# moonlight_application register map
Vendor: Nordic Semiconductor; Series: lumos; File version: 1
CPU: CM33 r0p4, little endian, MPU, FPU, 3 interrupt priority bits, 176 interrupts, 4 SAU regions
Registers are 32-bit, read-write, reset 0x0 unless marked. A register's access mark holds for its fields unless they carry their own. Offsets are from the block's base; [hi:lo] are bit positions; lines under a group give offsets from that group; {n}, {i} and the like mark numbered series; 'fields as' and 'values as' point back to an identical list.

## GLOBAL_RADIO_NS (part 4 of 4) — 2.4 GHz radio 0
Base 0x4008A000
Same registers: GLOBAL_RADIO_S 0x5008A000
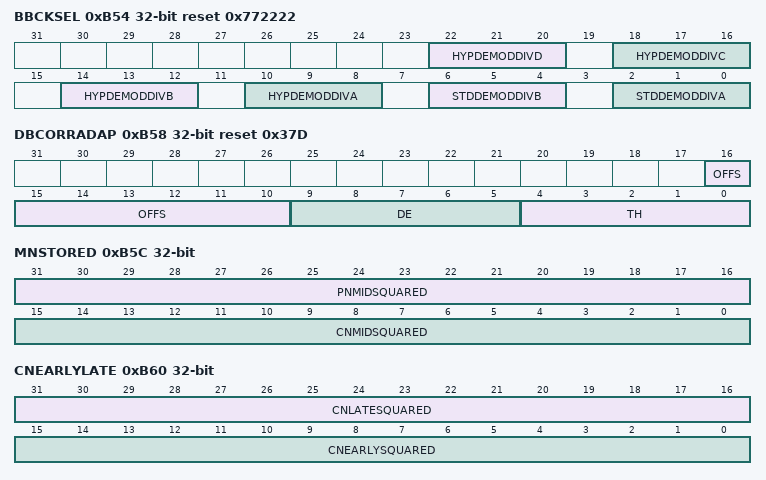
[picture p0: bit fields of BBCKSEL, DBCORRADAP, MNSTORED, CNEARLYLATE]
0xB54 BBCKSEL reset 0x772222 — Clock rates
  [22:20] HYPDEMODDIVD — Hyper demod clock divider D (max 4MHz)
    3=4M (Clock 4MHz); 4=2M (Clock 2MHz); 5=1M (Clock 1MHz); 6=500K (Clock 500kHz); 7=Disabled (Clock OFF)
  [18:16] HYPDEMODDIVC — Hyper demod clock divider C (max 8MHz)
    2=8M (Clock 8MHz); 3=4M (Clock 4MHz); 4=2M (Clock 2MHz); 5=1M (Clock 1MHz); 6=500K (Clock 500kHz); 7=Disabled (Clock OFF)
  [14:12] HYPDEMODDIVB — Hyper demod clock divider B
    0=32M (Clock 32MHz); 1=16M (Clock 16MHz); 2=8M (Clock 8MHz); 3=4M (Clock 4MHz); 4=2M (Clock 2MHz); 5=1M (Clock 1MHz); 6=500K (Clock 500kHz); 7=Disabled (Clock OFF)
  [10:8] HYPDEMODDIVA — Hyper demod clock divider A
    values as HYPDEMODDIVB
  [6:4] STDDEMODDIVB — Standard demod clock divider B
    values as HYPDEMODDIVB
  [2:0] STDDEMODDIVA — Standard demod clock divider A
    values as HYPDEMODDIVB
0xB58 DBCORRADAP reset 0x37D — Adaptive thresholds for double correlator.
  [16:10] OFFS — Offset for comparing between current and historical DBC magnitude
  [9:5] DE — A ratio to decay the DBC ration threshold when using adaptive threshold and a weak peak is found.
  [4:0] TH — A ratio to update the DBC ratio threshold when adaptive threshold is enabled and a strong peak is found. Fraction of highest correlator match historically seen. Setting of 0.90625 is default.
0xB5C MNSTORED ro — Stored value of Cn and Pn from the double correlator at the last detect
  [31:16] PNMIDSQUARED — Squared value of Cn which can be used to find Mn associated with the last double correlator detect
  [15:0] CNMIDSQUARED — Squared value of Cn which can be used to find Mn associated with the last double correlator detect
0xB60 CNEARLYLATE ro — The Cn value associated with the clock cycle before and after the actually double correlator peak was found (detect)
  [31:16] CNLATESQUARED — Squared value of Cn after the peak
  [15:0] CNEARLYSQUARED — Squared value of Cn before the peak
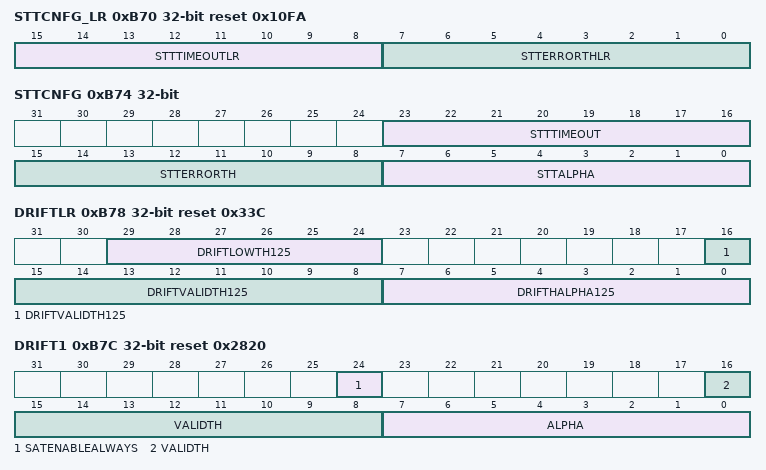
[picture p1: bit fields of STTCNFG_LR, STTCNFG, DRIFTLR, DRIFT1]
0xB70 STTCNFG_LR reset 0x10FA — Strobe time tracking configuration in long range mode
  [15:8] STTTIMEOUTLR — Strobe time tracking timeout in BLE LR mode
  [7:0] STTERRORTHLR — Strobe time tracking error threshold in BLE LR mode
0xB74 STTCNFG — Strobe time tracking Configuration (Symbol Timing)
  [23:16] STTTIMEOUT — Strobe time tracking: adjustment timeout (min distance in symbolperiods between strobe adjustments in same direction)
  [15:8] STTERRORTH — Strobe time tracking: strobe time error threshold
  [7:0] STTALPHA — Strobe time tracking: IIR filter alpha
0xB78 DRIFTLR reset 0x33C — Drift Controls in Long Range
  [29:24] DRIFTLOWTH125 — Override value for driftLowTh, drift estimator (despreadLELLong)
  [16:8] DRIFTVALIDTH125 — Override value for driftValidTh, drift estimator (despreadLELLong)
  [7:0] DRIFTHALPHA125 — Override value for IIR feedback , drift estimator (despreadLELLong)
0xB7C DRIFT1 reset 0x2820 — Drift Estimator configuration
  [24] SATENABLEALWAYS — Enable saturation in drift calculator for all modes
  [16:8] VALIDTH — Override value for driftValidTh, drift estimator (hypermode)
  [7:0] ALPHA — Override value for IIR feedback , drift estimator (hypermode)
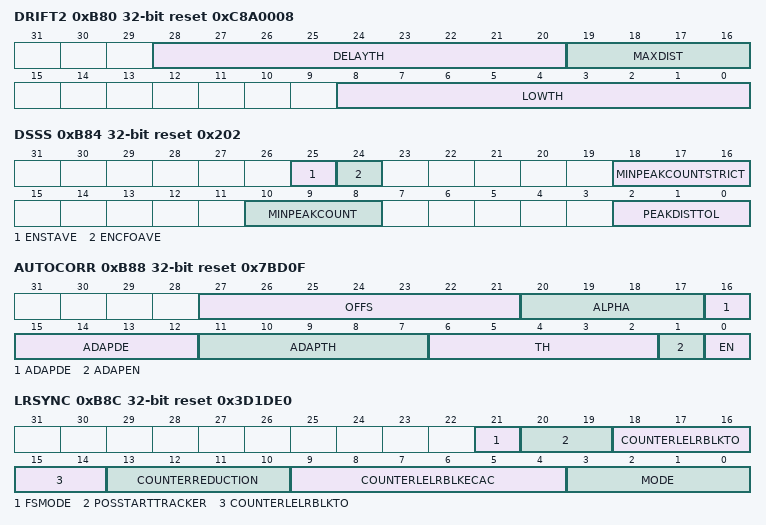
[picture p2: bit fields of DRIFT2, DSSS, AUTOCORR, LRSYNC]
0xB80 DRIFT2 reset 0xC8A0008 — Drift Estimator configuration
  [28:20] DELAYTH — Override value for driftDelayTh, drift estimator (hypermode)
  [19:16] MAXDIST — Override value for driftMaxDist, drift estimator (hypermode)
  [8:0] LOWTH — Override value for driftLowTh, drift estimator (hypermode)
0xB84 DSSS reset 0x202 — DSSS synchronizer trim values
  [25] ENSTAVE — Enable strobe time averaging
  [24] ENCFOAVE — Enable CFO averaging
  [18:16] MINPEAKCOUNTSTRICT — Min number of peaks to detect before resyncing to another preamble while already working on a previous preamble in BleLrx. Also applies for Ieee 802.15.4 mode
  [10:8] MINPEAKCOUNT — Override for dsssMinPeakCount
  [2:0] PEAKDISTTOL — Override for dsssPeakDistanceTolerance
0xB88 AUTOCORR reset 0x7BD0F — Autocorrelator configuration
  [27:21] OFFS — Offset for comparing between current and historical AC magnitude
  [20:17] ALPHA — Gain factor for low pass filter used to smoothen autocorrelator output. Set to 0000 indicates to select Max filter instead of LPF.
  [16:12] ADAPDE — A ratio to decay the autocorrelator ratio threshold when using adaptive threshold and a weak peak is found.
  [11:7] ADAPTH — A ratio to update the autocorrelator ratio threshold when adaptive threshold is enabled and a strong peak is found. Fraction of highest correlator match historically seen. Setting of 0.8125 is default.
  [6:2] TH — Default correlator threshold for deciding if valid correlator match is seen. Low setting of 0.10 is default.
  [1] ADAPEN — Enable adaptive autocorrelator threshold settings based on historically observed correlator output values.
  [0] EN — Enable autocorrelator gating of peaks.
0xB8C LRSYNC reset 0x3D1DE0 — LrSyncEngine configuration
  [21] FSMODE — Select between classic and MLSD based frame sync
    0=classic mode; 1=MLSD mode
  [20:19] POSSTARTTRACKER — A toggle to tell when to start the trackers inside each LelrBlk125.
    0=disabled for all times; 1=enabled after FEC1 is decoded; 2=enabled after frame sync is achieved; 3=enabled after LelrBlk125 is activated
  [18:14] COUNTERLELRBLKTO — A counter is used to reset the LelrBlk125 block that is active. It counts the number of outputs from DeSpreadLELong and compares it with this configured value to see whether a timeout event happens. The range is 32 to 60. Default value is 52.
  [13:10] COUNTERREDUCTION — When a strong peak event is triggered and the average peak strength is higher than the history stored in the block, the timeout counter is reduced by the number configured in this register. The default value is 7.
  [9:4] COUNTERLELRBLKECAC — A counter is used to indicate the time window of e-CAC check. It counts the number of outputs from DeSpreadLELong and compares it with this configured value to see whether e-CAC result is valid.
  [3:0] MODE — Modifying how the multiple lr125Front modules are used when synchronizing.
    0=AllFrontends (Use all the front ends); 1=OneFrontend (Use only one front end)
0xB90 QOVERRIDE26 reset 0x1 — Override for selecting whether to use LrSyncEngine or the classic demodulator.
  [0] USELRSYNCENGINE — Select whether to use LrSyncEngine or the classic demodulator.
    0=Classic (use classic demodulator); 1=LrSyncEngine (Use LrSyncEngine demodulator)
0xB94 QOVERRIDE27 reset 0x1 — Override for selecting whether to use enhanced IEEE 802.15.4 or the classic IEEE 802.15.4 demodulator.
  [0] USE154SYNCENGINE — Select whether to use enhanced IEEE 802.15.4 or the classic IEEE 802.15.4 demodulator.
    0=Classic (Use classic demodulator); 1=Ieee154SyncEngine (Use IEEE 802.15.4 sync demodulator)
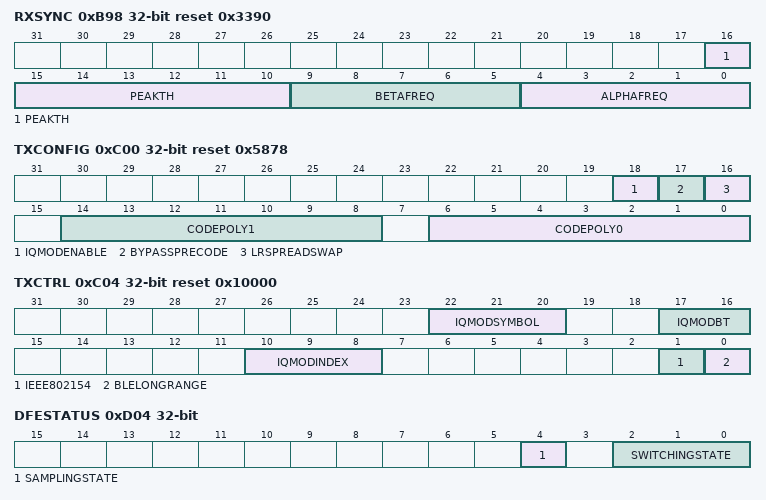
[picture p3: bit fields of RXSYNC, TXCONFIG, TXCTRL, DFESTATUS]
0xB98 RXSYNC reset 0x3390 — RxSyncEngine configuration
  [16:10] PEAKTH — Threshold value for peak strength. Default value is 0001100, corresponds to 0.31.
  [9:5] BETAFREQ — Coefficient to update frequency offset. Default value is 11100, corresponds to 7/8.
  [4:0] ALPHAFREQ — Coefficient to update frequency offset. Default value is 10000, corresponds to 1/2.
0xC00 TXCONFIG reset 0x5878 — Tx configuration
  [18] IQMODENABLE — Enable IQ modulator
    0=Disabled; 1=Enabled
  [17] BYPASSPRECODE — Bypass MSK precoding
    0=NotBypassed (Disable); 1=Bypassed (Enable)
  [16] LRSPREADSWAP — Swap pattern mapping. Default 0, 0 is mapped to a 0011 sequence, 1 is mapped to a 1100 sequence. If swap bit is set, 1 is mapped to a 0011 sequence, 0 is mapped to a 1100 sequence.
  [14:8] CODEPOLY1 — Code polynomial 1
  [6:0] CODEPOLY0 — Code polynomial 0
0xC04 TXCTRL reset 0x10000 — Tx control
  [22:20] IQMODSYMBOL — IQMOD additional symbol mapping not set by MODE(Future)
  [17:16] IQMODBT — IQMOD GFSK bandwidth
    0=0BT55 (BT=0.55); 1=0BT60 (BT=0.60)
  [10:8] IQMODINDEX — IQMOD modulation index
    0=ModIndex0h25 (Modulation index = 0.25(Future)); 1=ModIndex0h32 (Modulation index = 0.32(Future)); 2=ModIndex0h5 (Modulation index = 0.5(Future)); 3=ModIndex1h0 (Modulation index = 1(Future)); 4=ModIndex2h0 (Modulation index = 2(Future))
  [1] IEEE802154 — Enable Tx for Ieee802154_250Kbit mode and long range modes (Do not enable both Ieee802154_250Kbit and long range)
    0=Disabled (Disable Tx for Ieee802154_250Kbit mode); 1=Enabled (Enable Tx for Ieee802154_250Kbit mode)
  [0] BLELONGRANGE — Enable Tx for BLE long range modes (Do not enable both Ieee802154_250Kbit and BLE long range)
    0=Disabled (Disable Tx for BLE long range modes); 1=Enabled (Enable Tx for BLE long range modes)
0xD00 DFEMODE — Whether to use Angle-of-Arrival (AOA) or Angle-of-Departure (AOD)
  [1:0] DFEOPMODE — Direction finding operation mode
    0=Disabled (Direction finding mode disabled); 2=AoD (Direction finding mode set to AoD); 3=AoA (Direction finding mode set to AoA)
0xD04 DFESTATUS ro — DFE status information
  [4] SAMPLINGSTATE — Internal state of sampling state machine
    0=Idle (Sampling state Idle); 1=Sampling state Sampling
  [2:0] SWITCHINGSTATE — Internal state of switching state machine
    0=Idle (Switching state Idle); 1=Offset (Switching state Offset); 2=Guard (Switching state Guard); 3=Ref (Switching state Ref); 4=Switching state Switching; 5=Ending (Switching state Ending)
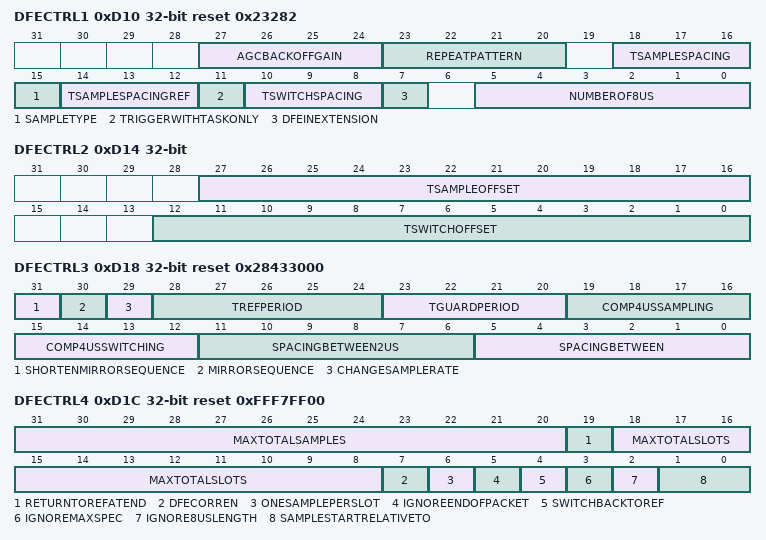
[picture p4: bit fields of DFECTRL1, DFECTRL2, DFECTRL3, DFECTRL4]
0xD10 DFECTRL1 reset 0x23282 — Various configuration for Direction finding
  [27:24] AGCBACKOFFGAIN — Gain will be lowered by the specified number of gain steps at the start of CTE
  [23:20] REPEATPATTERN — Repeat every antenna pattern N times.
    0=NoRepeat (Do not repeat (1 time in total))
  [18:16] TSAMPLESPACING — Interval between samples in the SWITCHING period when CTEINLINECTRLEN is 0
    1=4us; 2=2us; 3=1us; 4=500ns (0.5us); 5=250ns (0.25us); 6=125ns (0.125us)
  [15] SAMPLETYPE — Whether to sample I/Q or magnitude/phase
    0=IQ (Complex samples in I and Q); 1=MagPhase (Complex samples as magnitude and phase)
  [14:12] TSAMPLESPACINGREF — Interval between samples in the REFERENCE period
    0=8us; 1=4us; 2=2us; 3=1us; 4=500ns (0.5us); 5=250ns (0.25us); 6=125ns (0.125us)
  [11] TRIGGERWITHTASKONLY — Trigger AoA/AoD procedure using only task
    1=OnlyTask (Only allow triggering a procedure with TASKS_DFESTART); 0=Multiple (Trigger also with other signals)
  [10:8] TSWITCHSPACING — Interval between every time the antenna is changed in the SWITCHING state
    0=8us; 1=4us; 2=2us; 3=1us; 4=500ns (0.5us); 5=250ns (0.25us)
  [7] DFEINEXTENSION — Add CTE extension and do antenna switching/sampling in this extension
    1=CRC (AoA/AoD procedure triggered at end of CRC); 0=Payload (Antenna switching/sampling is done in the packet payload)
  [5:0] NUMBEROF8US — Length of the AoA/AoD procedure in number of 8 us units
0xD14 DFECTRL2 — Start offset for Direction finding
  [27:16] TSAMPLEOFFSET — Signed value offset before starting sampling in number of 16M cycles relative to the beginning of the REFERENCE state - 12 us after switching start
  [12:0] TSWITCHOFFSET — Signed value offset after the end of the CRC before starting switching in number of 16M cycles
0xD18 DFECTRL3 reset 0x28433000 — Various hacker/tuning configuration for Direction finding
  [31] SHORTENMIRRORSEQUENCE — Applies only when MIRRORSEQUENCE is set. Selects whether to repeat the end pattern (in both ends) or not
    0=Disabled (End patterns are repeated); 1=Enabled (End patterns are not repeated)
  [30] MIRRORSEQUENCE — When reaching the last antenna pattern, it repeats that pattern, and then goes back down again.
    0=Disabled (Do not mirror the sequence); 1=Enabled (Mirror the sequence)
  [29] CHANGESAMPLERATE — Whether to have the ability to have separate sampling rate in the REFERENCE period vs the SWITCHING state
    0=Same (Always use sample spacing given by TSAMPLESPACINGREF); 1=Change (Use TSAMPLESPACINGREF in the REFERENCE period, and TSAMPLESPACING or CTEINLINEAODRXMODExUS in the SWITCHING period)
  [28:24] TREFPERIOD — Length of REFERENCE period in number of microseconds, normally 8
  [23:20] TGUARDPERIOD — Length of GUARD period in number of microseconds, normally 4
  [19:16] COMP4USSAMPLING — Number of 4us periods to subtract from numberOf8us when calculating total number of samples to capture
  [15:12] COMP4USSWITCHING — Number of 4us periods to subtract from numberOf8us when calculating total number of antenna slots switches
  [11:6] SPACINGBETWEEN2US — Same as SPACINGBETWEEN when using CTEINLINECTRL and CTEType is 2 us slots
  [5:0] SPACINGBETWEEN — Signed tuning value for the spacing between the last sample in the reference period and the first sample in the first sample slot
0xD1C DFECTRL4 reset 0xFFF7FF00 — Various hacker/tuning configuration for Direction finding
  [31:20] MAXTOTALSAMPLES — Maximum number of samples to capture
  [19] RETURNTOREFATEND — Start position of repeated part of switching pattern sequence
    0=Disabled (Return to SWITCHPATTERN[2] after reaching the end of the switching pattern sequence); 1=Enabled (Return to SWITCHPATTERN[1] after reaching the end of the switching pattern sequence)
  [18:8] MAXTOTALSLOTS — Maximum number of antenna slots
  [7] DFECORREN — Enable correlator before Direction Finding samples
    0=Disabled (Disable correlator); 1=Enabled (Enable correlator)
  [6] ONESAMPLEPERSLOT — TSAMPLESPACING is ignored for the samples taken in the SWITCHING state TSAMPLESPACINGREF is still used for the first samples (REFERENCE period)
  [5] IGNOREENDOFPACKET — Ignore that the UTxRxChain says that the packet has been received Continue running if more time to run
    0=Do not ignore the end of packet; 1=Ignore the end of packet
  [4] SWITCHBACKTOREF — Insert reference antenna(SWITCHPATTERN[1]) between antenna switches, from SWITCHPATTERN[2] onwards
    0=Disabled (Do not insert reference antenna between switches); 1=Enabled (Insert reference antenna between switches)
  [3] IGNOREMAXSPEC — Ignore the maximum number of samples and antenna slots specified with MAXTOTALSAMPLES and MAXTOTALSLOTS
    0=DoNotIgnore (Use the max specs); 1=Ignore the max specs
  [2] IGNORE8USLENGTH — Ignore the length specification in numberOf8us
    0=DoNotIgnore (Use the length specification); 1=Ignore the length specification
  [1:0] SAMPLESTARTRELATIVETO — Start point of TSAMPLEOFFSET sampling relative to which part in the switching state machine
    0=Reference (At the start of the reference antenna period); 1=Switching (At the start of antenna switching after the reference antenna period); 2=Trigger (When it is triggered Either TASKS_DFESTART, address match or AoA/AoD procedure trigger source); 3=Guard (At the start of the GUARD period)
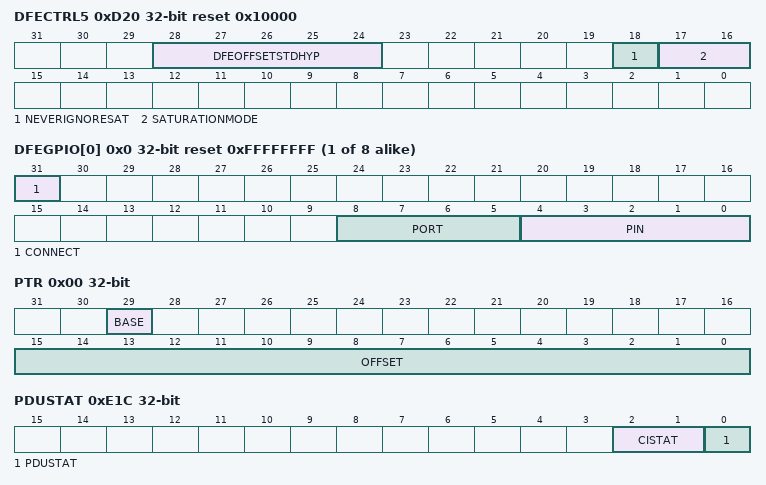
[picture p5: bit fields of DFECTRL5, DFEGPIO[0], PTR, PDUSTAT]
0xD20 DFECTRL5 reset 0x10000 — Various hacker/tuning configuration for Direction finding
  [28:24] DFEOFFSETSTDHYP — Tuning of the timing difference between the hypermode demodulator and the standard demodulator for the DFE start event, in 62.5 ns units
  [18] NEVERIGNORESAT — Selects whether saturation (being reported from the radio front-end) should be ignored in the beginning of the slot or not
    0=IGNORE (Saturation being indicated from the front-end is ignored if it happens in the first 40 percent of the sample spacing after a sample was saved to RAM); 1=NEVERIGNORE (Saturation is always reported in RAM if detected by the frontend)
  [17:16] SATURATIONMODE — Set how input saturation will be present in the captured samples
    0=OFF (No saturation is presented); 1=SETMINVAL (Saturation is marked by setting both I and Q to -32768 (or mag/phase if SAMPLETYPE is 1)); 2=SATURATIONBIT (Bit 15 of both the I and Q values indicates saturation. I and Q are hence only 15 bit values)
0xD28 SWITCHPATTERN — GPIO patterns to be used for each antenna
  [7:0] SWITCHPATTERN — Fill array of GPIO patterns for antenna control
0xD2C CLEARPATTERN wo — Clear the GPIO pattern array for antenna control
  [0] CLEARPATTERN — Clear the GPIO pattern array for antenna control Behaves as a task register, but does not have PPI nor IRQ
0xD30 PSEL group — Unspecified
  {0x0+4j} DFEGPIO[{j}] (j=0..7) reset 0xFFFFFFFF — Description collection: Pin select for DFE pin n
    [31] CONNECT — Connection
      1=Disconnected; 0=Connected
    [8:5] PORT — Port number
    [4:0] PIN — Pin number
0xD50 DFEPACKET group — DFE packet EasyDMA channel
  0x00 PTR — Data pointer
    [29] BASE
    [15:0] OFFSET — Data pointer
  0x04 MAXCNT reset 0x4000 — Maximum number of bytes to transfer
    [15:0] MAXCNT
  0x08 AMOUNT ro — Number of bytes transferred in the last transaction
    [15:0] AMOUNT
  0x0C CURRENTAMOUNT ro — Number of bytes transferred in the current transaction
    [15:0] AMOUNT — Number of bytes transferred in the current transaction. Continuously updated.
  0x10 ENABLE — Register present but not in use
    [0] ENABLE
      1=Disabled; 0=Enabled
  0x14 MODE wo reset 0x1 — Configure EasyDMA mode
    [0] LPOP — Enable low-power operation, or use low-latency
      0=Low-latency operation; 1=Low-power operation
0xD68 DFEDMASTART wo — Manually start DmaChannelPeripheral for DFE
  [0] DFEDMASTART
0xD6C DFEDMASTOP wo — Force stop DmaChannelPeripheral for DFE
  [0] DFEDMASTOP
0xD70 DFEDMAAHBERROR ro — Points to where the AHB error occured
  [31:0] ERROR — The error
0xE00 CNTPSTART wo — Start packet counter
  [0] TRIG
0xE04 CNTPSTOP wo — Stop packet counter
  [0] TRIG
0xE08 CNTPCLEAR wo — Clear packet counter
  [0] TRIG
0xE0C CRCSTATUS ro
  [0] CRCSTATUS — CRC status of packet received
    0=CRCError (Packet received with CRC error); 1=CRCOk (Packet received with CRC ok)
0xE10 RXMATCH ro — Received address
  [2:0] RXMATCH
0xE14 RXCRC ro — CRC field of previously received packet
  [23:0] RXCRC
0xE18 DAI ro — Device address match index
  [2:0] DAI
0xE1C PDUSTAT ro — Payload status
  [2:1] CISTAT — Status on what rate packet is received with in Long Range
    0=LR125kbit (Frame is received at 125 kbps); 1=LR500kbit (Frame is received at 500 kbps)
  [0] PDUSTAT — Status on payload length vs. PCNF1.MAXLEN
    0=LessThan (Payload less than PCNF1.MAXLEN); 1=GreaterThan (Payload greater than PCNF1.MAXLEN)
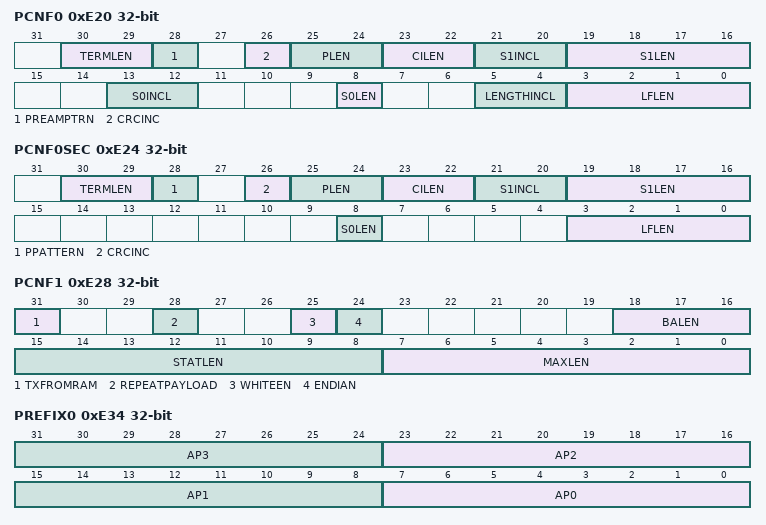
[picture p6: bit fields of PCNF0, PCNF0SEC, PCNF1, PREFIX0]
0xE20 PCNF0 — Packet configuration register 0
  [30:29] TERMLEN — Length of TERM field in Long Range operation
  [28] PREAMPTRN — Preamble pattern
  [26] CRCINC — Indicates if LENGTH field contains CRC or not
    0=Exclude (LENGTH does not contain CRC); 1=Include (LENGTH includes CRC)
  [25:24] PLEN — Length of preamble on air. Decision point: TASKS_START task
    0=8-bit preamble; 1=16-bit preamble; 2=32-bit zero preamble - used for IEEE 802.15.4; 3=LongRange (Preamble - used for BLE long range)
  [23:22] CILEN — Length of code indicator - long range
  [21:20] S1INCL — Include or exclude S1 field in RAM
    0=Automatic (Include S1 field in RAM only if S1LEN > 0); 1=Include (Always include S1 field in RAM independent of S1LEN)
  [19:16] S1LEN — Length on air of S1 field in number of bits.
  [13:12] S0INCL — Include or exclude S0 field in RAM
    0=Automatic (Include S0 field only if S0LEN > 0)
  [8] S0LEN — Length on air of S0 field in number of bytes.
  [5:4] LENGTHINCL — Include or exclude LENGTH field in RAM
    0=Automatic (Include LENGTH field in RAM only if LFLEN > 0)
  [3:0] LFLEN — Length on air of LENGTH field in number of bits.
0xE24 PCNF0SEC — Packet configuration register 0 in concurrent receive mode in BLE LR
  [30:29] TERMLEN — Length of TERM field in Long Range operation
  [28] PPATTERN
  [26] CRCINC — Indicates if LENGTH field contains CRC or not
    values as PCNF0.CRCINC
  [25:24] PLEN — Length of preamble on air. Decision point: TASKS_START task
    values as PCNF0.PLEN
  [23:22] CILEN — Length of code indicator - long range
  [21:20] S1INCL — Include or exclude S1 field in RAM
    values as PCNF0.S1INCL
  [19:16] S1LEN — Length on air of S1 field in number of bits.
  [8] S0LEN — Length on air of S0 field in number of bytes.
  [3:0] LFLEN — Length on air of LENGTH field in number of bits.
0xE28 PCNF1 — Packet configuration register 1
  [31] TXFROMRAM — Used to bypass PREAMBLE, ADDRESS, S0, LENGTH, S1 field and go straight to PAYLOAD state
    0=Disabled; 1=Bypass
  [28] REPEATPAYLOAD — Used to repeat payload content in Tx mode. Transmits PREAMBLE, ADDRESS once, but S0, LENGTH, S1 field size must be set to 0 to avoid repeating those as well
    0=Disabled; 1=Enabled
  [25] WHITEEN — Enable or disable packet whitening
    0=Disabled; 1=Enabled
  [24] ENDIAN — On-air endianness of packet, this applies to the S0, LENGTH, S1, and the PAYLOAD fields.
    0=Little (Least significant bit on air first); 1=Big (Most significant bit on air first)
  [18:16] BALEN — Base address length in number of bytes
  [15:8] STATLEN — Static length in number of bytes
  [7:0] MAXLEN — Maximum length of packet payload. If the packet payload is larger than MAXLEN, the radio will truncate the payload to MAXLEN.
0xE2C BASE0 — Base address 0
0xE30 BASE1 — Base address 1
0xE34 PREFIX0 — Prefixes bytes for logical addresses 0-3
  [8n+7:8n] AP{n} (n=0..3) — Address prefix {n}
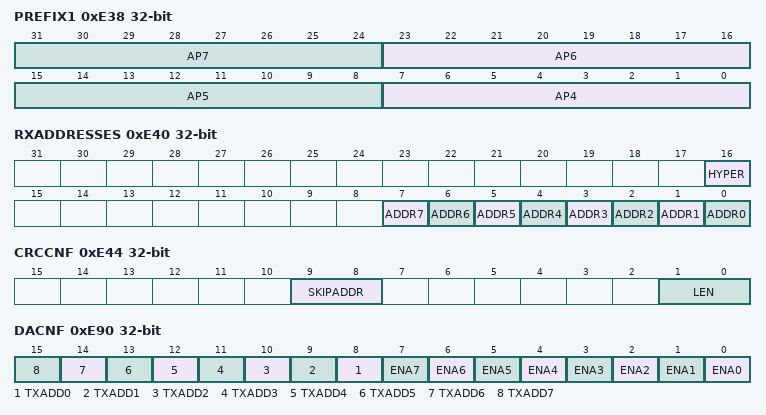
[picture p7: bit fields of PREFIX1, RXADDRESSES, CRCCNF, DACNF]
0xE38 PREFIX1 — Prefixes bytes for logical addresses 4-7
  [8n-25:8n-32] AP{n} (n=4..7) — Address prefix {n}
0xE3C TXADDRESS — Transmit address select
  [2:0] TXADDRESS
0xE40 RXADDRESSES — Receive address select
  [16] HYPER — Hypermode settings
    0=B0 (Use hypermode for address ADDR0 (base address 0 RADIO.BASE0)); 1=B1 (From all of the enabled addresses among ADDR1 through ADDR7, the address ADDRn with the highest index number 'n' will use hypermode (base address 1 RADIO.BASE1))
  [n] ADDR{n} (n=0..7) — Enable or disable reception on logical address {n}
    0=Disabled; 1=Enabled
0xE44 CRCCNF — CRC configuration
  [9:8] SKIPADDR — Include or exclude packet address field out of CRC calculation.
    0=Include (CRC calculation includes address field); 1=Skip (CRC calculation does not include address field. The CRC calculation will start at the first byte after the address.); 2=Ieee802154 (CRC calculation as per 802.15.4 standard. Starting at first byte after length field.)
  [1:0] LEN — CRC length in number of bytes.
    0=Disabled (CRC length is zero and CRC calculation is disabled); 1=One (CRC length is one byte and CRC calculation is enabled); 2=Two (CRC length is two bytes and CRC calculation is enabled); 3=Three (CRC length is three bytes and CRC calculation is enabled)
0xE48 CRCPOLY — CRC polynomial
  [23:0] CRCPOLY
0xE4C CRCINIT — CRC initial value
  [23:0] CRCINIT
{0xE50+4i} DAB[{i}] (i=0..7) — Description collection: Device address base segment n
  [31:0] DAB — Device address base segment n
{0xE70+4i} DAP[{i}] (i=0..7) — Description collection: Device address prefix n
  [15:0] DAP — Device address prefix n
0xE90 DACNF — Device address match configuration
  [n+8] TXADD{n} (n=0..7) — TxAdd for device address {n}
  [n] ENA{n} (n=0..7) — Enable or disable device address matching using device address {n}
    0=Disabled; 1=Enabled
0xE94 BCC — Bit counter compare
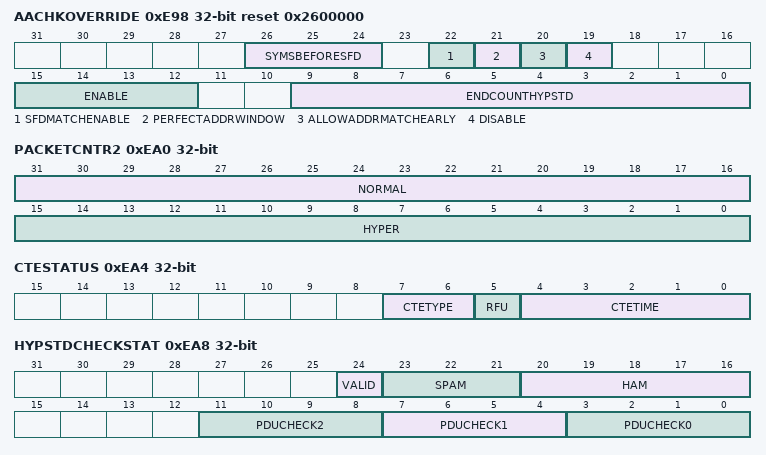
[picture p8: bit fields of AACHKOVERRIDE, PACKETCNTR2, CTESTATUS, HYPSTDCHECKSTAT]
0xE98 AACHKOVERRIDE reset 0x2600000 — Address Check Override
  [26:24] SYMSBEFORESFD — Number of preamble symbols before SFD to match, by default 2 symbols.
  [22] SFDMATCHENABLE — Enable every 4 bits SFD match for IEEE 802.15.4
    0=Disabled; 1=Enabled
  [21] PERFECTADDRWINDOW — Enable timing accurate address match window in demodulator
    0=Disabled (The address window has some margin); 1=Enabled (The address window spans only one bit)
  [20] ALLOWADDRMATCHEARLY — Enable ignore std AA checker before shift register filled
    0=Enabled; 1=Disabled
  [19] DISABLE — Disable std AA checker
    0=Enabled (Enable std AA checker); 1=Disabled (Disable std AA checker)
  [15:12] ENABLE — Enable AA bit 15 check
    0=AA16to31 (Enable AA16..31); 1=AA15to31 (Enable AA15..31); 2=AA14to31 (Enable AA14..31); 3=AA13to31 (Enable AA13..31); 4=AA12to31 (Enable AA12..31); 5=AA11to31 (Enable AA11..31); 6=AA10to31 (Enable AA10..31); 7=AA9to31 (Enable AA9..31); 8=AA8to31 (Enable AA8..31 (when 32-bit AA is enabled)); 9=AA7to31 (Enable AA7..31 (when 32-bit AA is enabled)); 10=AA6to31 (Enable AA6..31 (when 32-bit AA is enabled)); 11=AA5to31 (Enable AA5..31 (when 32-bit AA is enabled)); 12=AA4to31 (Enable AA4..31 (when 32-bit AA is enabled)); 13=AA3to31 (Enable AA3..31 (when 32-bit AA is enabled)); 14=AA2to31 (Enable AA2..31 (when 32-bit AA is enabled)); 15=AA1to31 (Enable AA1..31 (when 32-bit AA is enabled))
  [9:0] ENDCOUNTHYPSTD — Defines maximum number of PDU bits to compare between Hyper and Std demodulator
0xE9C PACKETCNTR1 ro — Unspecified
  [15:0] COUNTER — Packet counter value
0xEA0 PACKETCNTR2 ro — Unspecified
  [31:16] NORMAL — Packet counter value (number of packets with addressmatch ok)
  [15:0] HYPER — Number of detected correlator syncs
0xEA4 CTESTATUS ro — CTEInfo parsed from received packet
  [7:6] CTETYPE — CTEType parsed from packet
  [5] RFU — RFU parsed from packet
  [4:0] CTETIME — CTETime parsed from packet
0xEA8 HYPSTDCHECKSTAT ro — Address Check Override
  [24] VALID — Valid flag bit
  [23:21] SPAM — Time distance #bit clock cycles from AAmatchHyp.
  [20:16] HAM — Hamming distance between std demod AA15:0 and expected AA15:0.
  [11:8] PDUCHECK2 — Number of bits where Std and Hyper demodulator disagrees for maximum latency.
  [7:4] PDUCHECK1 — Number of bits where Std and Hyper demodulator disagrees for medium latency.
  [3:0] PDUCHECK0 — Number of bits where Std and Hyper demodulator disagrees for minimum latency.
0xEAC HYPSTDAADIFFVEC ro — Address Diff Vector
  [15:0] DIFF — Hyper AA15:0 and Std AA15:0 differs
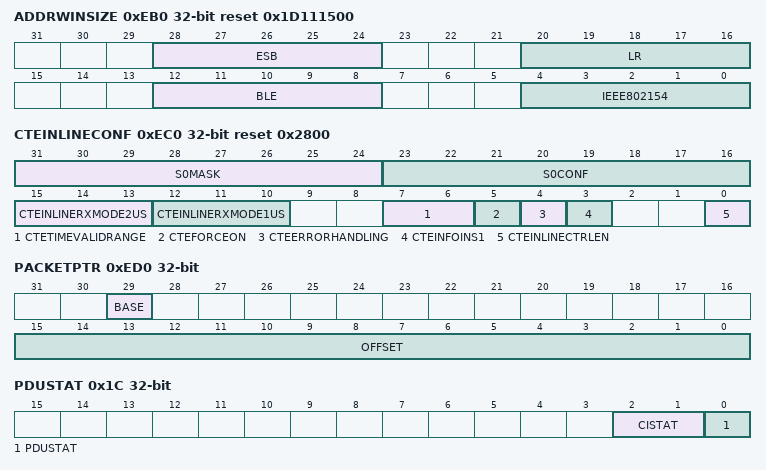
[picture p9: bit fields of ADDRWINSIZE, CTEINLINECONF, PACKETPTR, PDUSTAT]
0xEB0 ADDRWINSIZE reset 0x1D111500 — Address match safe window size (the number of bits after detect is asserted, before starting to look for address match). Only valid when OVERRIDE22.DISABLEADDRWINDOW is '0'.
  [28:24] ESB — Number of bits after detect to start search address/SFD in ESB mode
  [20:16] LR — Number of bits after detect to start search address/SFD in BLE_LR_125k/BLE_LR_500k mode
  [12:8] BLE — Number of bits after detect to start search address/SFD in BLE mode
  [4:0] IEEE802154 — Number of bits after detect to start search address/SFD in IEEE 802.15.4 mode Default value for classic 802.15.4 sync is 0x18
0xEB4 MHRMATCHCONF — Search pattern configuration
0xEB8 MHRMATCHMASK — Pattern mask
0xEBC SFD reset 0xA7 — IEEE 802.15.4 start of frame delimiter
  [7:0] SFD
0xEC0 CTEINLINECONF reset 0x2800 — Configuration for CTE inline mode
  [31:24] S0MASK — S0 bit mask to set which bit to match
  [23:16] S0CONF — S0 bit pattern to match
  [15:13] CTEINLINERXMODE2US — Spacing between samples for the samples in the SWITCHING period when CTEINLINEMODE is set
    values as DFECTRL1.TSAMPLESPACINGREF
  [12:10] CTEINLINERXMODE1US — Spacing between samples for the samples in the SWITCHING period when CTEINLINEMODE is set
    values as DFECTRL1.TSAMPLESPACINGREF
  [7:6] CTETIMEVALIDRANGE — Max range of CTETime
    0=20 in 8us unit (default) Set to 20 if parsed CTETime is larger han 20; 1=31 in 8us unit; 2=63 in 8us unit
  [5] CTEFORCEON — CTE is continuously output after CRC and only stopped by triggering TASKS_STOP. This is typically used together with the DFEEND to STOP short. AoA/AoD procedure duration is still controlled by DFECTRL1.NUMBEROF8S / CTETIME
    1=Yes (CTE is continuously transmitted after CRC until TASKS_STOP); 0=No (CTE duration is automatically determined by DFECTRL1.NUMBEROF8US / CTETIME (only correct for 1Mbps and 2Mbps modes))
  [4] CTEERRORHANDLING — Sampling/switching if CRC is not OK
    1=Yes (Sampling and antenna switching also when CRC is not OK); 0=No (No sampling and antenna switching when CRC is not OK)
  [3] CTEINFOINS1 — CTEInfo is S1 byte or not
    1=InS1 (CTEInfo is in S1 byte (data PDU)); 0=NotInS1 (CTEInfo is NOT in S1 byte (advertising PDU))
  [0] CTEINLINECTRLEN — Enable parsing of CTEInfo from received packet in BLE modes
    1=Enabled (Parsing of CTEInfo is enabled); 0=Disabled (Parsing of CTEInfo is disabled)
0xEC4 DMASTART wo — Unspecified
  [0] TRIG
0xEC8 DMASTOP wo — Unspecified
  [0] TRIG
0xECC DMAENABLE — Unspecified
  [0] ENABLE
0xED0 PACKETPTR — Unspecified
  [29] BASE, [15:0] OFFSET
0xED4 DMAAMOUNT ro — Unspecified
  [8:0] AMOUNT
0xED8 DMAMAXCNT reset 0x103 — Unspecified
  [8:0] MAXCNT
0xF00 LBMAC group — Unspecified
  0x00 CNTPSTART wo — Start packet counter
    [0] TRIG
  0x04 CNTPSTOP wo — Stop packet counter
    [0] TRIG
  0x08 CNTPCLEAR wo — Clear packet counter
    [0] TRIG
  0x0C CRCSTATUS ro
    fields as CRCSTATUS
  0x10 RXMATCH ro — Received address
    [2:0] RXMATCH
  0x14 RXCRC ro — CRC field of previously received packet
    [23:0] RXCRC
  0x18 DAI ro — Device address match index
    [2:0] DAI
  0x1C PDUSTAT ro — Payload status
    fields as PDUSTAT
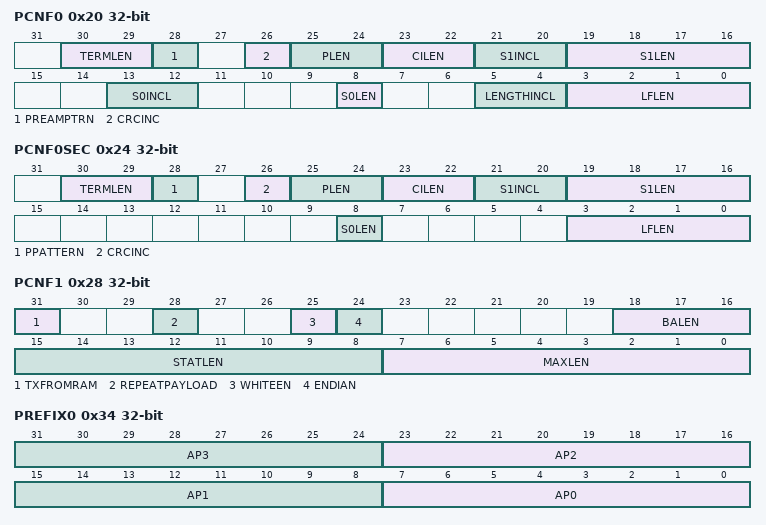
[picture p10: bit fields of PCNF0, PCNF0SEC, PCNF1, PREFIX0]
  0x20 PCNF0 — Packet configuration register 0
    fields as PCNF0
  0x24 PCNF0SEC — Packet configuration register 0 in concurrent receive mode in BLE LR
    fields as PCNF0SEC
  0x28 PCNF1 — Packet configuration register 1
    fields as PCNF1
  0x2C BASE0 — Base address 0
  0x30 BASE1 — Base address 1
  0x34 PREFIX0 — Prefixes bytes for logical addresses 0-3
    [8n+7:8n] AP{n} (n=0..3) — Address prefix {n}
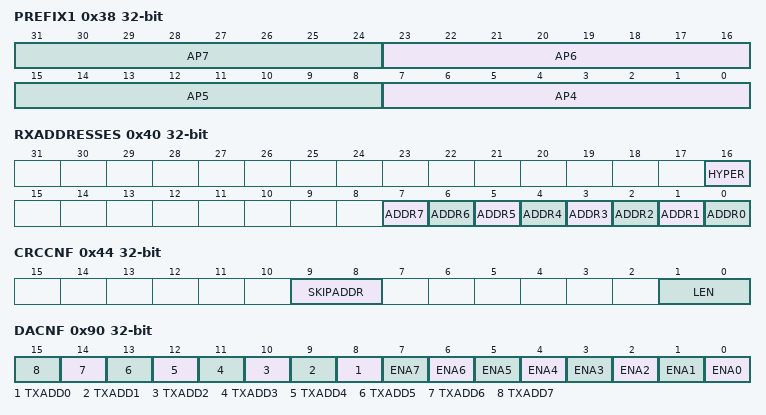
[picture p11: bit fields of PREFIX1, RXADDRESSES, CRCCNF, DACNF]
  0x38 PREFIX1 — Prefixes bytes for logical addresses 4-7
    [8n-25:8n-32] AP{n} (n=4..7) — Address prefix {n}
  0x3C TXADDRESS — Transmit address select
    [2:0] TXADDRESS
  0x40 RXADDRESSES — Receive address select
    fields as RXADDRESSES
  0x44 CRCCNF — CRC configuration
    fields as CRCCNF
  0x48 CRCPOLY — CRC polynomial
    [23:0] CRCPOLY
  0x4C CRCINIT — CRC initial value
    [23:0] CRCINIT
  {0x50+4j} DAB[{j}] (j=0..7) — Description collection: Device address base segment n
    [31:0] DAB — Device address base segment n
  {0x70+4j} DAP[{j}] (j=0..7) — Description collection: Device address prefix n
    [15:0] DAP — Device address prefix n
  0x90 DACNF — Device address match configuration
    fields as DACNF
  0x94 BCC — Bit counter compare
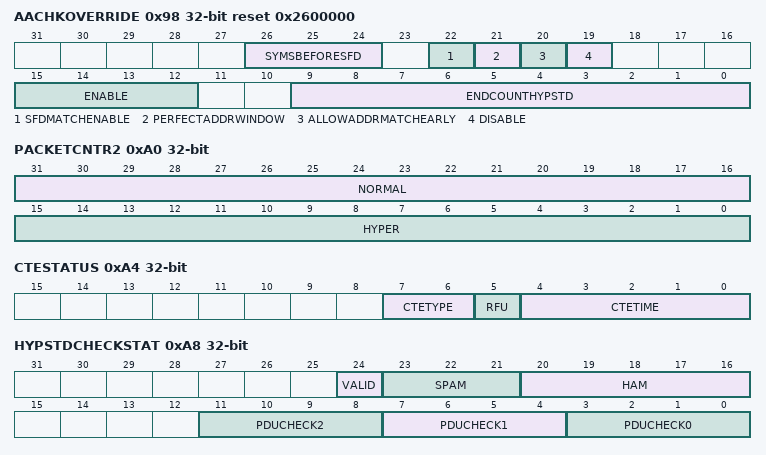
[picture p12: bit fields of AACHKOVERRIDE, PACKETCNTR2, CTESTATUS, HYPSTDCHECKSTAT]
  0x98 AACHKOVERRIDE reset 0x2600000 — Address Check Override
    fields as AACHKOVERRIDE
  0x9C PACKETCNTR1 ro — Unspecified
    [15:0] COUNTER — Packet counter value
  0xA0 PACKETCNTR2 ro — Unspecified
    fields as PACKETCNTR2
  0xA4 CTESTATUS ro — CTEInfo parsed from received packet
    fields as CTESTATUS
  0xA8 HYPSTDCHECKSTAT ro — Address Check Override
    fields as HYPSTDCHECKSTAT
  0xAC HYPSTDAADIFFVEC ro — Address Diff Vector
    [15:0] DIFF — Hyper AA15:0 and Std AA15:0 differs
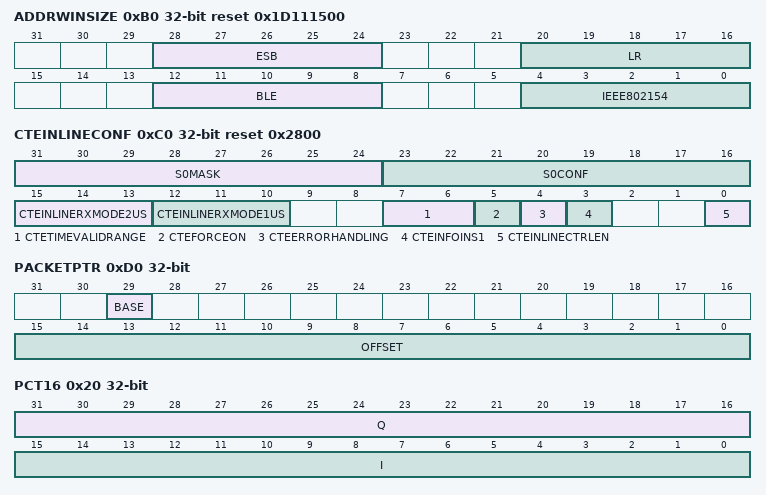
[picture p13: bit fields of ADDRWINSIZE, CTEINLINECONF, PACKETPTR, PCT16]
  0xB0 ADDRWINSIZE reset 0x1D111500 — Address match safe window size (the number of bits after detect is asserted, before starting to look for address match). Only valid when OVERRIDE22.DISABLEADDRWINDOW is '0'.
    fields as ADDRWINSIZE
  0xB4 MHRMATCHCONF — Search pattern configuration
  0xB8 MHRMATCHMASK — Pattern mask
  0xBC SFD reset 0xA7 — IEEE 802.15.4 start of frame delimiter
    [7:0] SFD
  0xC0 CTEINLINECONF reset 0x2800 — Configuration for CTE inline mode
    fields as CTEINLINECONF
  0xC4 DMASTART wo — Unspecified
    [0] TRIG
  0xC8 DMASTOP wo — Unspecified
    [0] TRIG
  0xCC DMAENABLE — Unspecified
    [0] ENABLE
  0xD0 PACKETPTR — Unspecified
    [29] BASE, [15:0] OFFSET
  0xD4 DMAAMOUNT ro — Unspecified
    [8:0] AMOUNT
  0xD8 DMAMAXCNT reset 0x103 — Unspecified
    [8:0] MAXCNT
0x1000 CSTONES group — Unspecified
  0x00 MODE reset 0x3 — Selects the mode that are activated on the start signal
    [1:0] MODE — Selecting TPM, TFM or both
      0=TPM; 1=TFM
  0x04 NUMSAMPLES reset 0xA0 — Number of input samples at 2MHz sample rate.
    [7:0] NUMSAMPLES — Maximum value supported is 160
  0x08 NEXTFREQUENCY — The value of FREQUENCY that will be used in the next step.
    [6:0] NEXTFREQUENCY — Frequency = 2400 + FREQUENCY (MHz).
  0x0C FFOIN — Override value of FFO (Fractional Frequency Offset) if not to be based on the frequency estimate derived from CnAcc (autocorrelation of the scaled input signal) value.
    [11:0] FFFIN — Units 62.5 ppb. Max range +/-100 ppm plus margin.
  0x10 FFOSOURCE reset 0x1 — Source of FFO
    [0] FFOSOURCE
      0=FfoIn (Use FFOIN); 1=CnAcc (Calculate FFO from CnAcc)
  0x14 FAEPEER — FAEPEER (Frequency Actuation Error) of peer if known. Used during Mode 0 steps.
    [7:0] FAEPEER — Units 31.25 ppb.
  0x18 PHASESHIFT — Parameter used in TPM, provided by software
    [15:0] PHASESHIFT — Phase shift used in TPM calculation
  0x1C NUMSAMPLESCOEFF reset 0x199A — Parameter used in TPM, provided by software
    [15:0] NUMSAMPLESCOEFF — Coefficient 1/(numSamples/16) in Q1.15 format (Default numsamples value is 160)
  0x20 PCT16 ro — Mean magnitude and mean phase converted to IQ.
    [31:16] Q — Quadrature
    [15:0] I — In_phase
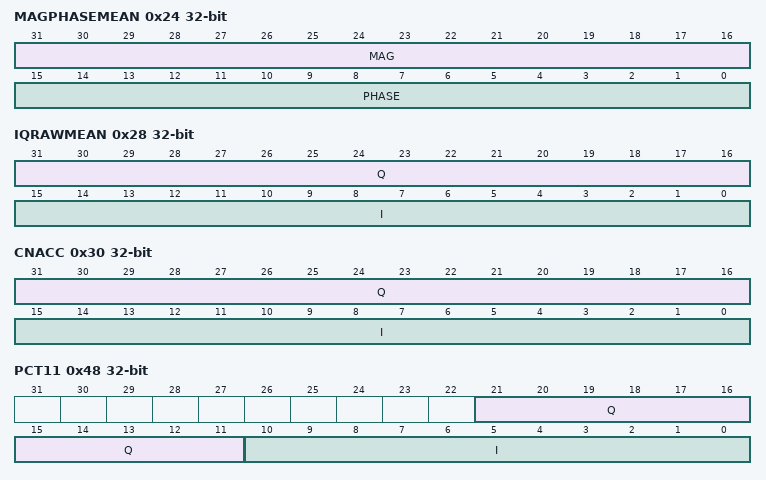
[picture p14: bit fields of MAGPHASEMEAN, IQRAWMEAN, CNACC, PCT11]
  0x24 MAGPHASEMEAN ro — Mean magnitude and phase of the signal before it is converted to PCT16
    [31:16] MAG — Mean magnitude.
    [15:0] PHASE — Mean phase.
  0x28 IQRAWMEAN ro — Mean of IQ values.
    [31:16] Q — Quadrature
    [15:0] I — Inphase
  0x2C MAGSTD ro — Magnitude standard deviation approximation.
    [15:0] MAGSTD
  0x30 CNACC ro — Output of the autocorrelation of the accumulated IQ signal.
    [31:16] Q — Quadrature
    [15:0] I — Inphase
  0x34 FFOEST ro — FFO estimate.
    [11:0] FFOEST — Units 62.5 ppb. Max range +/-100 ppm plus margin.
  0x3C FINETUNENEXT ro — Number of full ADPLL finetune steps.
    [12:0] FINETUNENEXT — Units of 488.28125 Hz
  0x40 CFOPHASE ro — Cordic output of CnAcc.
    [15:0] CFOPHASE
  0x44 FREQOFFSET ro — Frequency offset estimate.
    [13:0] FREQOFFSET
  0x48 PCT11 ro — Mean magnitude and mean phase converted to IQ. IQ values limited to –[1024,1023]
    [21:11] Q — Quadrature
    [10:0] I — Inphase
  0x4C LFAENEXT ro — Quantization error between ADPLL frequency and the desired value of FFO * RF Frequency. Values limited to –[64,63] with units 7.6294 Hz
    [6:0] LFAENEXT — Inphase
0x1D00 DFT group — Unspecified
  0x00 DTB0CONFIG — Digital Test Bus 0 (DTB0) configuration
    [31] EN — Enable the digital test bus
      0=Disabled (Digital test bus is disabled); 1=Enabled (Digital test bus is enabled)
    [1:0] SELMUX — Select multiplexer for DTB0
      0=AnaDtb00 (SPHYNX_DTB0_AO_0V8[0]); 1=AafDcCalI (SPHYNX_AAF_DCCAL_I_AO_0V8); 2=RxPkDet0 (SPHYNX_RX_PKDET_AO_0V8[0]); 3=Spare (None selected, logic 0)
  0x04 DTB1CONFIG — Digital Test Bus 1 (DTB1) configuration
    [31] EN — Enable the digital test bus
      values as DFT.DTB0CONFIG.EN
    [1:0] SELMUX — Select multiplexer for DTB1
      0=AnaDtb01 (SPHYNX_DTB0_AO_0V8[1]); 1=AafDcCalQ (SPHYNX_AAF_DCCAL_Q_AO_0V8); 2=RfPkDet1 (SPHYNX_RX_PKDET_AO_0V8[1]); 3=Spare (None selected, logic 0)
  0x08 DTB2CONFIG — Digital Test Bus 2 (DTB2) configuration
    [31] EN — Enable the digital test bus
      values as DFT.DTB0CONFIG.EN
    [1:0] SELMUX — Select multiplexer for DTB2
      0=AnaDtb02 (SPHYNX_DTB0_AO_0V8[2]); 1=PllSettled; 2=FsSpareOutputs0 (SPHYNX_FS_SPARE_OUTPUTS_AO_0V8[0]); 3=Spare (None selected, logic 0)
  0x0C DTB3CONFIG — Digital Test Bus 3 (DTB3) configuration
    [31] EN — Enable the digital test bus
      values as DFT.DTB0CONFIG.EN
    [1:0] SELMUX — Select multiplexer for DTB3
      0=AnaDtb03 (SPHYNX_DTB0_AO_0V8[3]); 1=FsTxDataReq (SPHYNX_FS_TXDATAREQ_AO_0V8); 2=CalCmpRcCal (SPHYNX_CAL_CMP_RCCAL_AO_0V8); 3=Spare (None selected, logic 0)
0x1F00 PENALTYTRIGPCP4 group — Unspecified
  0x00 ZERO wo — Unspecified
    [0] TRIG
  0x04 FULL wo — Unspecified
    [0] TRIG
0x1F08 PENALTYTRIGPCP3 group — Unspecified
  0x00 ZERO wo — Unspecified
    [0] TRIG
  0x04 FULL wo — Unspecified
    [0] TRIG
0x1F10 PENALTYTRIGPCP2 group — Unspecified
  0x00 ZERO wo — Unspecified
    [0] TRIG
  0x04 FULL wo — Unspecified
    [0] TRIG
0x1F18 PENALTYTRIGPCP1 group — Unspecified
  0x00 ZERO wo — Unspecified
    [0] TRIG
  0x04 FULL wo — Unspecified
    [0] TRIG
0x1F20 PENALTYTRIGPCP0 group — Unspecified
  0x00 ZERO wo — Unspecified
    [0] TRIG
  0x04 FULL wo — Unspecified
    [0] TRIG
0x1F28 PENALTYREG group — Unspecified
  0x00 PCP0 wo — Unspecified
    [31:0] VALUE
  {0x0+4j} PCP[{j}] (j=0..3) wo reset 0xFFFFFFFC (alternate view of PCP0) — Description collection:
    [31:0] VALUE
0x1F3C AUTOCLOCKSOURCEREQ ro — Unspecified
  [all] fields
    0=On (Unspecified); 1=Off (Unspecified)
  [n] PCP_{n} (n=0..4)
0x1F40 FORCEOVERRIDE group — Unspecified
  {0x0+4j} PCP[{j}] (j=0..4) — Description collection:
    [7] DOFORCECLOCK, [1] CLOCKFORCING
